# MKW30Z4 register map
Vendor: Freescale Semiconductor, Inc.; Series: Kinetis_W; File version: 1.6
CPU: CM0PLUS r0p0, little endian, no MPU, no FPU, VTOR, 2 interrupt priority bits
Registers are 32-bit, read-write, reset 0x0 unless marked. A register's access mark holds for its fields unless they carry their own. Offsets are from the block's base; [hi:lo] are bit positions; {n}, {i} and the like mark numbered series; 'fields as' and 'values as' point back to an identical list.

## TRNG — RNG
Base 0x40029000
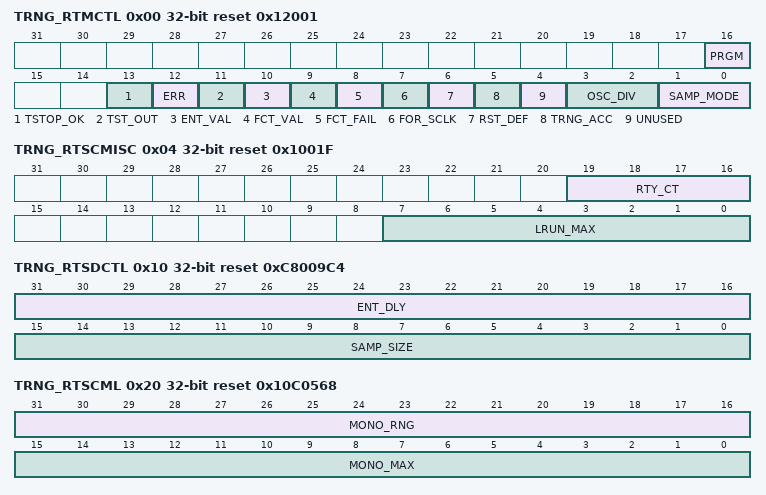
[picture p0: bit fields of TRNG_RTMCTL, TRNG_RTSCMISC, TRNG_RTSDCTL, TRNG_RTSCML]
0x00 TRNG_RTMCTL reset 0x12001 — RNG Miscellaneous Control Register
  [16] PRGM
  [13] TSTOP_OK ro
  [12] ERR
  [11] TST_OUT ro
  [10] ENT_VAL ro
  [9] FCT_VAL ro
  [8] FCT_FAIL ro
  [7] FOR_SCLK
  [6] RST_DEF wo
  [5] TRNG_ACC
  [4] UNUSED
  [3:2] OSC_DIV
    0=use ring oscillator with no divide; 1=use ring oscillator divided-by-2; 2=use ring oscillator divided-by-4; 3=use ring oscillator divided-by-8
  [1:0] SAMP_MODE
    0=use Von Neumann data into both Entropy shifter and Statistical Checker; 1=use raw data into both Entropy shifter and Statistical Checker; 2=use Von Neumann data into Entropy shifter. Use raw data into Statistical Checker
0x04 TRNG_RTSCMISC reset 0x1001F — RNG Statistical Check Miscellaneous Register
  [19:16] RTY_CT, [7:0] LRUN_MAX
0x08 TRNG_RTPKRRNG reset 0x9A3 — RNG Poker Range Register
  [15:0] PKR_RNG
0x0C TRNG_RTPKRMAX reset 0x6920 (TRNG view) — RNG Poker Maximum Limit Register
  [23:0] PKR_MAX
0x0C TRNG_RTPKRSQ ro (TRNG view) — RNG Poker Square Calculation Result Register
  [23:0] PKR_SQ
0x10 TRNG_RTSDCTL reset 0xC8009C4 — RNG Seed Control Register
  [31:16] ENT_DLY, [15:0] SAMP_SIZE
0x14 TRNG_RTSBLIM reset 0x3F (TRNG view) — RNG Sparse Bit Limit Register
  [9:0] SB_LIM
0x14 TRNG_RTTOTSAM ro (TRNG view) — RNG Total Samples Register
  [19:0] TOT_SAM
0x18 TRNG_RTFRQMIN reset 0x640 — RNG Frequency Count Minimum Limit Register
  [21:0] FRQ_MIN
0x1C TRNG_RTFRQCNT ro (TRNG view) — RNG Frequency Count Register
  [21:0] FRQ_CT
0x1C TRNG_RTFRQMAX reset 0x6400 (TRNG view) — RNG Frequency Count Maximum Limit Register
  [21:0] FRQ_MAX
0x20 TRNG_RTSCMC ro (TRNG view) — RNG Statistical Check Monobit Count Register
  [15:0] MONO_CT
0x20 TRNG_RTSCML reset 0x10C0568 (TRNG view) — RNG Statistical Check Monobit Limit Register
  [31:16] MONO_RNG, [15:0] MONO_MAX
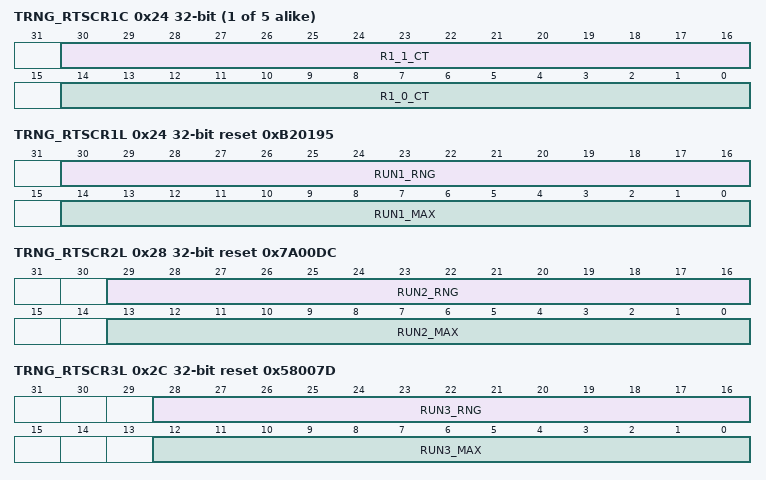
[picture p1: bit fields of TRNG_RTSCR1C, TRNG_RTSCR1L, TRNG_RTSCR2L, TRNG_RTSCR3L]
{0x20+4i} TRNG_RTSCR{i}C ro (TRNG view) (i=1..5) — RNG Statistical Check Run Length {i} Count Register
  [{31-i}:16] R{i}_1_CT, [{15-i}:0] R{i}_0_CT
0x24 TRNG_RTSCR1L reset 0xB20195 (TRNG view) — RNG Statistical Check Run Length 1 Limit Register
  [30:16] RUN1_RNG, [14:0] RUN1_MAX
0x28 TRNG_RTSCR2L reset 0x7A00DC (TRNG view) — RNG Statistical Check Run Length 2 Limit Register
  [29:16] RUN2_RNG, [13:0] RUN2_MAX
0x2C TRNG_RTSCR3L reset 0x58007D (TRNG view) — RNG Statistical Check Run Length 3 Limit Register
  [28:16] RUN3_RNG, [12:0] RUN3_MAX
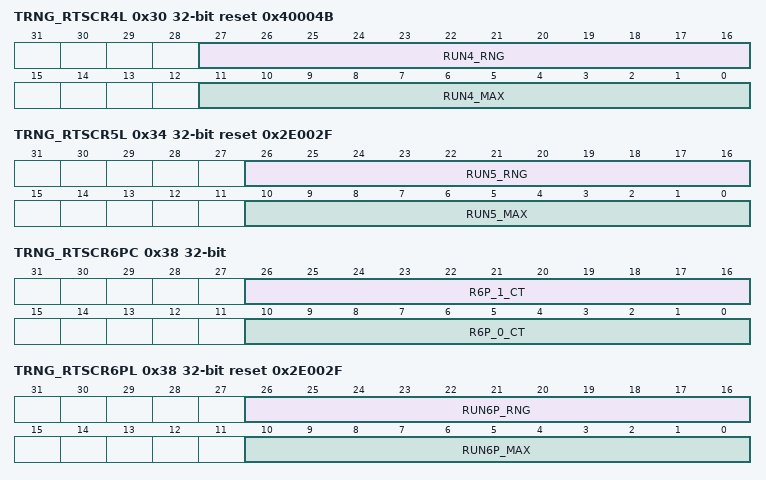
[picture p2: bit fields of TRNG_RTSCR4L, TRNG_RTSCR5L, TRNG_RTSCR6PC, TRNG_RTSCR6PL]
0x30 TRNG_RTSCR4L reset 0x40004B (TRNG view) — RNG Statistical Check Run Length 4 Limit Register
  [27:16] RUN4_RNG, [11:0] RUN4_MAX
0x34 TRNG_RTSCR5L reset 0x2E002F (TRNG view) — RNG Statistical Check Run Length 5 Limit Register
  [26:16] RUN5_RNG, [10:0] RUN5_MAX
0x38 TRNG_RTSCR6PC ro (TRNG view) — RNG Statistical Check Run Length 6+ Count Register
  [26:16] R6P_1_CT, [10:0] R6P_0_CT
0x38 TRNG_RTSCR6PL reset 0x2E002F (TRNG view) — RNG Statistical Check Run Length 6+ Limit Register
  [26:16] RUN6P_RNG, [10:0] RUN6P_MAX
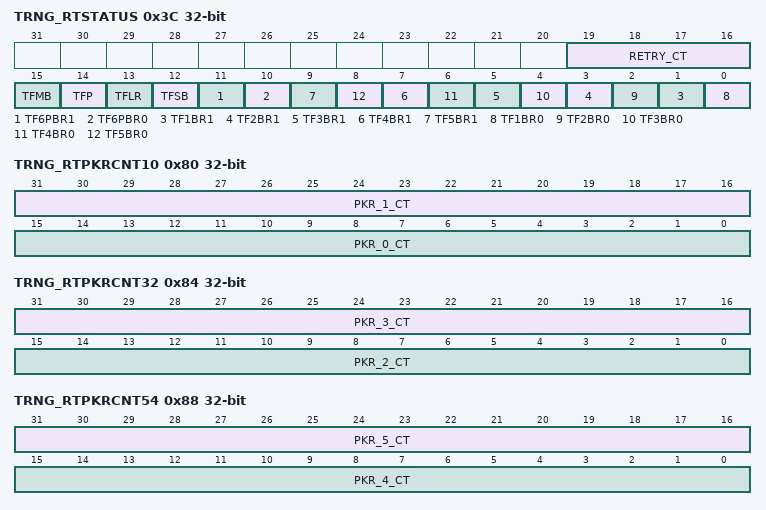
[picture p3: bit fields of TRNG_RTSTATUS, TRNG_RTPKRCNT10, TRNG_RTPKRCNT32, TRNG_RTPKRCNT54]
0x3C TRNG_RTSTATUS ro — RNG Status Register
  [19:16] RETRY_CT, [15] TFMB, [14] TFP, [13] TFLR, [12] TFSB, [11] TF6PBR1, [10] TF6PBR0, [2n-1] TF{n}BR1 (n=1..5), [2n-2] TF{n}BR0 (n=1..5)
{0x40+4i} TRNG_RTENT{i} ro (i=0..15) — RNG TRNG Entropy Read Register
  [31:0] ENT
0x80 TRNG_RTPKRCNT10 ro — RNG Statistical Check Poker Count 1 and 0 Register
  [31:16] PKR_1_CT, [15:0] PKR_0_CT
0x84 TRNG_RTPKRCNT32 ro — RNG Statistical Check Poker Count 3 and 2 Register
  [31:16] PKR_3_CT, [15:0] PKR_2_CT
0x88 TRNG_RTPKRCNT54 ro — RNG Statistical Check Poker Count 5 and 4 Register
  [31:16] PKR_5_CT, [15:0] PKR_4_CT
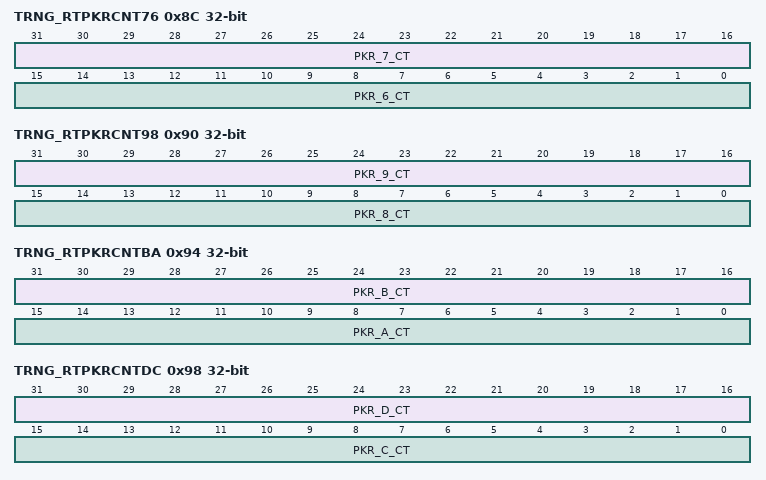
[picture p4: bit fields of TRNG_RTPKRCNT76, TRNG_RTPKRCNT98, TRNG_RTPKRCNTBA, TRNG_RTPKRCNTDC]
0x8C TRNG_RTPKRCNT76 ro — RNG Statistical Check Poker Count 7 and 6 Register
  [31:16] PKR_7_CT, [15:0] PKR_6_CT
0x90 TRNG_RTPKRCNT98 ro — RNG Statistical Check Poker Count 9 and 8 Register
  [31:16] PKR_9_CT, [15:0] PKR_8_CT
0x94 TRNG_RTPKRCNTBA ro — RNG Statistical Check Poker Count B and A Register
  [31:16] PKR_B_CT, [15:0] PKR_A_CT
0x98 TRNG_RTPKRCNTDC ro — RNG Statistical Check Poker Count D and C Register
  [31:16] PKR_D_CT, [15:0] PKR_C_CT
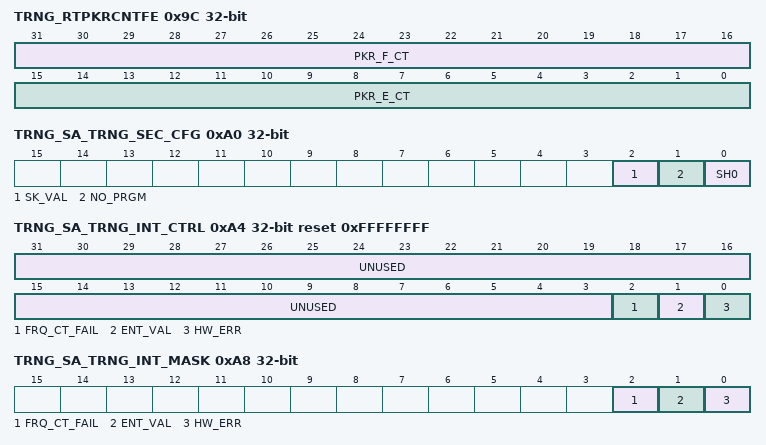
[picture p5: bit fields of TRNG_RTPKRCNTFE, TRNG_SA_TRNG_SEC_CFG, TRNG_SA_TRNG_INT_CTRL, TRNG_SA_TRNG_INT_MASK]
0x9C TRNG_RTPKRCNTFE ro — RNG Statistical Check Poker Count F and E Register
  [31:16] PKR_F_CT, [15:0] PKR_E_CT
0xA0 TRNG_SA_TRNG_SEC_CFG — RNG Security Configuration Register
  [2] SK_VAL
    0=See DRNG version; 1=See DRNG version
  [1] NO_PRGM
    0=Programability of registers controlled only by the RNG Miscellaneous Control Register's access mode bit; 1=Overides RNG Miscellaneous Control Register access mode and prevents TRNG register programming
  [0] SH0
    0=See DRNG version; 1=See DRNG version
0xA4 TRNG_SA_TRNG_INT_CTRL reset 0xFFFFFFFF — RNG Interrupt Control Register
  [31:3] UNUSED
  [2] FRQ_CT_FAIL
    0=Same behavior as bit 0 above; 1=Same behavior as bit 0 above
  [1] ENT_VAL
    values as FRQ_CT_FAIL
  [0] HW_ERR
    0=Corresponding bit of true cleared; 1=Corresponding bit of true active
0xA8 TRNG_SA_TRNG_INT_MASK — RNG Mask Register
  [2] FRQ_CT_FAIL
    values as TRNG_SA_TRNG_INT_CTRL.FRQ_CT_FAIL
  [1] ENT_VAL
    values as TRNG_SA_TRNG_INT_CTRL.FRQ_CT_FAIL
  [0] HW_ERR
    0=Corresponding interrupt of true is masked; 1=Corresponding bit of true is active
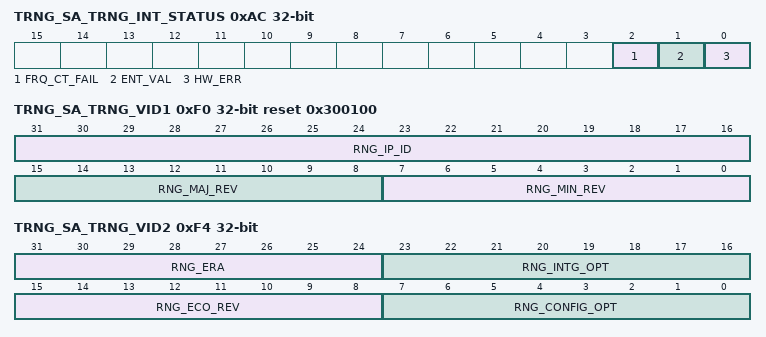
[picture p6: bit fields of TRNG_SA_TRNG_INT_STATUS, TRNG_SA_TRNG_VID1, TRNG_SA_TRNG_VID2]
0xAC TRNG_SA_TRNG_INT_STATUS — RNG Interrupt Status Register
  [2] FRQ_CT_FAIL
    0=No hardware nor self test frequency errors; 1=The frequency counter has detected a failure
  [1] ENT_VAL ro
    0=Busy generation entropy. Any value read is invalid.; 1=TRNG can be stopped and entropy is valid if read
  [0] HW_ERR ro
    0=no error; 1=error detected
0xF0 TRNG_SA_TRNG_VID1 ro reset 0x300100 — RNG Version ID Register (MS)
  [31:16] RNG_IP_ID
  [15:8] RNG_MAJ_REV
    0b0x01=Major revision number for TRNG
  [7:0] RNG_MIN_REV
    0b0x00=Minor revision number for TRNG
0xF4 TRNG_SA_TRNG_VID2 ro — RNG Version ID Register (LS)
  [31:24] RNG_ERA
    0b0x00=COMPILE_OPT for TRNG
  [23:16] RNG_INTG_OPT
    0b0x00=INTG_OPT for TRNG
  [15:8] RNG_ECO_REV
    0b0x00=TRNG_ECO_REV for TRNG
  [7:0] RNG_CONFIG_OPT
    0b0x00=TRNG_CONFIG_OPT for TRNG

## Notices in the file
Redistribution and use in source and binary forms, with or without modification,
are permitted provided that the following conditions are met:
o Redistributions of source code must retain the above copyright notice, this list
of conditions and the following disclaimer.
o Redistributions in binary form must reproduce the above copyright notice, this
list of conditions and the following disclaimer in the documentation and/or
other materials provided with the distribution.
o Neither the name of Freescale Semiconductor, Inc. nor the names of its
contributors may be used to endorse or promote products derived from this
software without specific prior written permission.
THIS SOFTWARE IS PROVIDED BY THE COPYRIGHT HOLDERS AND CONTRIBUTORS "AS IS" AND
ANY EXPRESS OR IMPLIED WARRANTIES, INCLUDING, BUT NOT LIMITED TO, THE IMPLIED
WARRANTIES OF MERCHANTABILITY AND FITNESS FOR A PARTICULAR PURPOSE ARE
DISCLAIMED. IN NO EVENT SHALL THE COPYRIGHT HOLDER OR CONTRIBUTORS BE LIABLE FOR
ANY DIRECT, INDIRECT, INCIDENTAL, SPECIAL, EXEMPLARY, OR CONSEQUENTIAL DAMAGES
(INCLUDING, BUT NOT LIMITED TO, PROCUREMENT OF SUBSTITUTE GOODS OR SERVICES;
LOSS OF USE, DATA, OR PROFITS; OR BUSINESS INTERRUPTION) HOWEVER CAUSED AND ON
ANY THEORY OF LIABILITY, WHETHER IN CONTRACT, STRICT LIABILITY, OR TORT
(INCLUDING NEGLIGENCE OR OTHERWISE) ARISING IN ANY WAY OUT OF THE USE OF THIS
SOFTWARE, EVEN IF ADVISED OF THE POSSIBILITY OF SUCH DAMAGE.
